# STM32F103C8 register map
Vendor: STMicroelectronics
CPU: CM3
Registers are 32-bit, access not given, reset 0x0 unless marked. A register's access mark holds for its fields unless they carry their own. Offsets are from the block's base; lines under a group give offsets from that group; [hi:lo] are bit positions; {n}, {i} and the like mark numbered series; 'fields as' and 'values as' point back to an identical list; <NAME> marks a mode.

## Memory map
0x40000000 TIM2 — General purpose timer
0x40010800 GPIOA — General purpose I/O A
0x40013800 USART1 — Universal synchronous/asynchronous receiver/transmitter
0x40021000 RCC — Reset and clock control

## RCC — Reset and clock control
Base 0x40021000
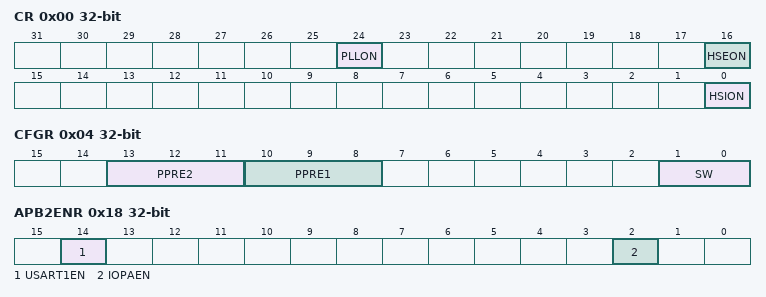
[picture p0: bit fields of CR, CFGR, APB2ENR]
0x00 CR — Clock control
  [24] PLLON, [16] HSEON, [0] HSION
0x04 CFGR — Clock configuration
  [13:11] PPRE2, [10:8] PPRE1, [1:0] SW
0x18 APB2ENR — APB2 peripheral clock enable
  [14] USART1EN, [2] IOPAEN

## GPIOA — General purpose I/O A
Base 0x40010800
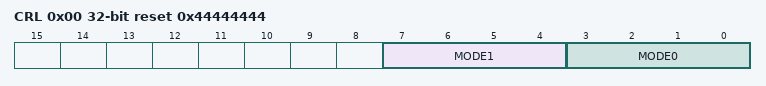
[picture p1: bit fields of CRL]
0x00 CRL reset 0x44444444 — Configuration low
  [7:4] MODE1, [3:0] MODE0
0x04 CRH reset 0x44444444 — Configuration high
0x08 IDR — Input data
0x0C ODR — Output data
0x10 BSRR — Bit set/reset

## USART1 — Universal synchronous/asynchronous receiver/transmitter
Base 0x40013800
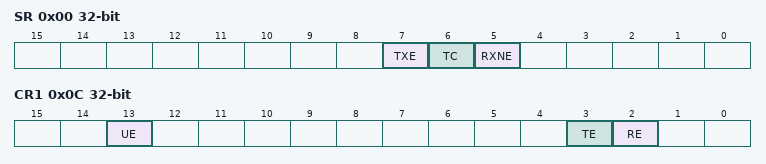
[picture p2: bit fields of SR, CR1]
0x00 SR — Status
  [7] TXE, [6] TC, [5] RXNE
0x04 DR — Data
0x08 BRR — Baud rate
0x0C CR1 — Control 1
  [13] UE, [3] TE, [2] RE

## TIM2 — General purpose timer
Base 0x40000000
0x00 CR1 — Control 1
0x24 CNT — Counter
0x28 PSC — Prescaler
0x2C ARR — Auto-reload
